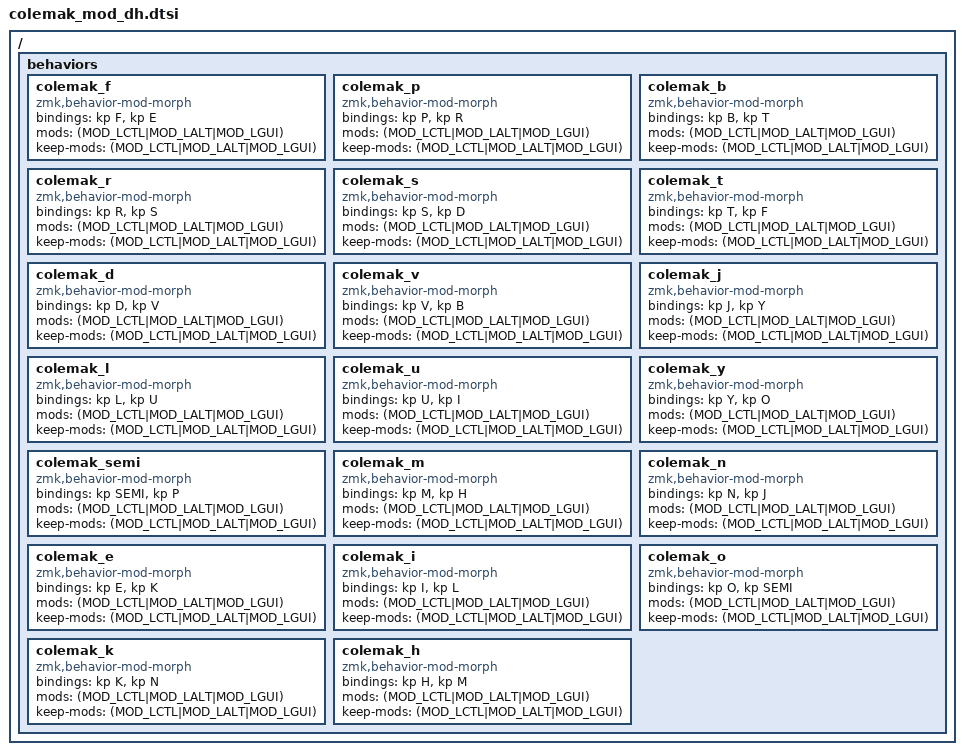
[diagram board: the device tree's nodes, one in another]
/ {
  behaviors {
    colemak_f: colemak_f {
      compatible = "zmk,behavior-mod-morph";
      #binding-cells = <0>;
      bindings = <&kp F>, <&kp E>;
      mods = <(MOD_LCTL|MOD_LALT|MOD_LGUI)>;
      keep-mods = <(MOD_LCTL|MOD_LALT|MOD_LGUI)>;
    };


    colemak_p: colemak_p {
      compatible = "zmk,behavior-mod-morph";
      #binding-cells = <0>;
      bindings = <&kp P>, <&kp R>;
      mods = <(MOD_LCTL|MOD_LALT|MOD_LGUI)>;
      keep-mods = <(MOD_LCTL|MOD_LALT|MOD_LGUI)>;
    };


    colemak_b: colemak_b {
      compatible = "zmk,behavior-mod-morph";
      #binding-cells = <0>;
      bindings = <&kp B>, <&kp T>;
      mods = <(MOD_LCTL|MOD_LALT|MOD_LGUI)>;
      keep-mods = <(MOD_LCTL|MOD_LALT|MOD_LGUI)>;
    };


    colemak_r: colemak_r {
      compatible = "zmk,behavior-mod-morph";
      #binding-cells = <0>;
      bindings = <&kp R>, <&kp S>;
      mods = <(MOD_LCTL|MOD_LALT|MOD_LGUI)>;
      keep-mods = <(MOD_LCTL|MOD_LALT|MOD_LGUI)>;
    };


    colemak_s: colemak_s {
      compatible = "zmk,behavior-mod-morph";
      #binding-cells = <0>;
      bindings = <&kp S>, <&kp D>;
      mods = <(MOD_LCTL|MOD_LALT|MOD_LGUI)>;
      keep-mods = <(MOD_LCTL|MOD_LALT|MOD_LGUI)>;
    };


    colemak_t: colemak_t {
      compatible = "zmk,behavior-mod-morph";
      #binding-cells = <0>;
      bindings = <&kp T>, <&kp F>;
      mods = <(MOD_LCTL|MOD_LALT|MOD_LGUI)>;
      keep-mods = <(MOD_LCTL|MOD_LALT|MOD_LGUI)>;
    };


    colemak_d: colemak_d {
      compatible = "zmk,behavior-mod-morph";
      #binding-cells = <0>;
      bindings = <&kp D>, <&kp V>;
      mods = <(MOD_LCTL|MOD_LALT|MOD_LGUI)>;
      keep-mods = <(MOD_LCTL|MOD_LALT|MOD_LGUI)>;
    };


    colemak_v: colemak_v {
      compatible = "zmk,behavior-mod-morph";
      #binding-cells = <0>;
      bindings = <&kp V>, <&kp B>;
      mods = <(MOD_LCTL|MOD_LALT|MOD_LGUI)>;
      keep-mods = <(MOD_LCTL|MOD_LALT|MOD_LGUI)>;
    };


    colemak_j: colemak_j {
      compatible = "zmk,behavior-mod-morph";
      #binding-cells = <0>;
      bindings = <&kp J>, <&kp Y>;
      mods = <(MOD_LCTL|MOD_LALT|MOD_LGUI)>;
      keep-mods = <(MOD_LCTL|MOD_LALT|MOD_LGUI)>;
    };


    colemak_l: colemak_l {
      compatible = "zmk,behavior-mod-morph";
      #binding-cells = <0>;
      bindings = <&kp L>, <&kp U>;
      mods = <(MOD_LCTL|MOD_LALT|MOD_LGUI)>;
      keep-mods = <(MOD_LCTL|MOD_LALT|MOD_LGUI)>;
    };


    colemak_u: colemak_u {
      compatible = "zmk,behavior-mod-morph";
      #binding-cells = <0>;
      bindings = <&kp U>, <&kp I>;
      mods = <(MOD_LCTL|MOD_LALT|MOD_LGUI)>;
      keep-mods = <(MOD_LCTL|MOD_LALT|MOD_LGUI)>;
    };


    colemak_y: colemak_y {
      compatible = "zmk,behavior-mod-morph";
      #binding-cells = <0>;
      bindings = <&kp Y>, <&kp O>;
      mods = <(MOD_LCTL|MOD_LALT|MOD_LGUI)>;
      keep-mods = <(MOD_LCTL|MOD_LALT|MOD_LGUI)>;
    };


    colemak_semi: colemak_semi {
      compatible = "zmk,behavior-mod-morph";
      #binding-cells = <0>;
      bindings = <&kp SEMI>, <&kp P>;
      mods = <(MOD_LCTL|MOD_LALT|MOD_LGUI)>;
      keep-mods = <(MOD_LCTL|MOD_LALT|MOD_LGUI)>;
    };


    colemak_m: colemak_m {
      compatible = "zmk,behavior-mod-morph";
      #binding-cells = <0>;
      bindings = <&kp M>, <&kp H>;
      mods = <(MOD_LCTL|MOD_LALT|MOD_LGUI)>;
      keep-mods = <(MOD_LCTL|MOD_LALT|MOD_LGUI)>;
    };


    colemak_n: colemak_n {
      compatible = "zmk,behavior-mod-morph";
      #binding-cells = <0>;
      bindings = <&kp N>, <&kp J>;
      mods = <(MOD_LCTL|MOD_LALT|MOD_LGUI)>;
      keep-mods = <(MOD_LCTL|MOD_LALT|MOD_LGUI)>;
    };


    colemak_e: colemak_e {
      compatible = "zmk,behavior-mod-morph";
      #binding-cells = <0>;
      bindings = <&kp E>, <&kp K>;
      mods = <(MOD_LCTL|MOD_LALT|MOD_LGUI)>;
      keep-mods = <(MOD_LCTL|MOD_LALT|MOD_LGUI)>;
    };


    colemak_i: colemak_i {
      compatible = "zmk,behavior-mod-morph";
      #binding-cells = <0>;
      bindings = <&kp I>, <&kp L>;
      mods = <(MOD_LCTL|MOD_LALT|MOD_LGUI)>;
      keep-mods = <(MOD_LCTL|MOD_LALT|MOD_LGUI)>;
    };


    colemak_o: colemak_o {
      compatible = "zmk,behavior-mod-morph";
      #binding-cells = <0>;
      bindings = <&kp O>, <&kp SEMI>;
      mods = <(MOD_LCTL|MOD_LALT|MOD_LGUI)>;
      keep-mods = <(MOD_LCTL|MOD_LALT|MOD_LGUI)>;
    };


    colemak_k: colemak_k {
      compatible = "zmk,behavior-mod-morph";
      #binding-cells = <0>;
      bindings = <&kp K>, <&kp N>;
      mods = <(MOD_LCTL|MOD_LALT|MOD_LGUI)>;
      keep-mods = <(MOD_LCTL|MOD_LALT|MOD_LGUI)>;
    };


    colemak_h: colemak_h {
      compatible = "zmk,behavior-mod-morph";
      #binding-cells = <0>;
      bindings = <&kp H>, <&kp M>;
      mods = <(MOD_LCTL|MOD_LALT|MOD_LGUI)>;
      keep-mods = <(MOD_LCTL|MOD_LALT|MOD_LGUI)>;
    };
  };
};
